# 3065PNPIMH register map
File version: 1.0
Registers are 32-bit, access per field, reset 0x0 unless marked. A register's access mark holds for its fields unless they carry their own. Offsets are from the block's base; [hi:lo] are bit positions; {n}, {i} and the like mark numbered series.

## CRG — CRG peripheral interface
Base 0x10000000
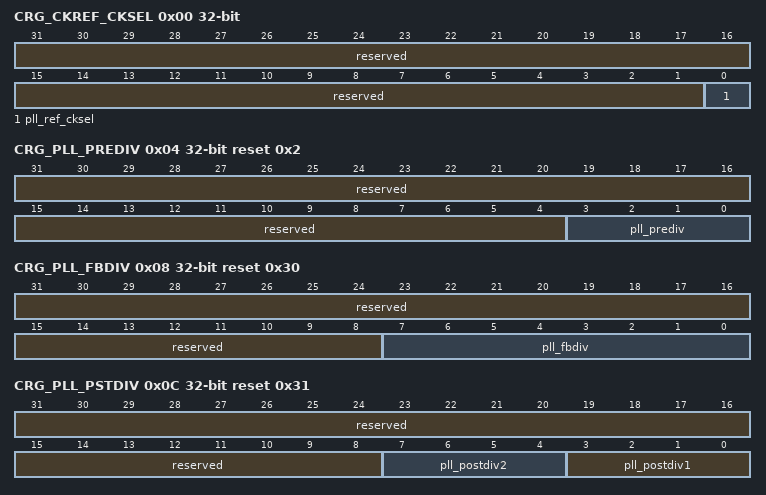
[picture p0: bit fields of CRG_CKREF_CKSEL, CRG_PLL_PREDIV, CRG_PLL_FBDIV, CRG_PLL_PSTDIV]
0x00 CRG_CKREF_CKSEL — CRG_CKREF_CKSEL为PLL配置寄存器0。 该寄存器可以被寄存器SC_LOCKEN[crg_cfg_lock]写保护控制，只有禁用写保护时，对这个寄存器的写操作才有效。
  [31:1] reserved ro — 保留。
  [0] pll_ref_cksel rw — PLL输入参考时钟clk_pll_ref时钟源选择信号。 0：选择clk_hosc； 1：选择clk_xtal。
0x04 CRG_PLL_PREDIV reset 0x2 — CRG_PLL_PREDIV为PLL配置寄存器1。 该寄存器可以被寄存器SC_LOCKEN[crg_cfg_lock]写保护控制，只有禁用写保护时，对这个寄存器的写操作才有效。
  [31:4] reserved ro — 保留。
  [3:0] pll_prediv rw — PLL内部前置分频器分频比。 0x0：1分频； 0x1：2分频； 0x2：3分频； 0x3：4分频； 0x4：5分频； 0x5：6分频； 0x6：7分频； 0x7：8分频； 其他：未使用。
0x08 CRG_PLL_FBDIV reset 0x30 — CRG_PLL_FBDIV为PLL配置寄存器2。 该寄存器可以被寄存器SC_LOCKEN[crg_cfg_lock]写保护控制，只有禁用写保护时，对这个寄存器的写操作才有效。
  [31:8] reserved ro — 保留。
  [7:0] pll_fbdiv rw — PLL内部反馈分频器分频比。 0x00 ～ 0x06：6分频； 0x07 ~ 0x7F：7~127分频； 其他：未使用。
0x0C CRG_PLL_PSTDIV reset 0x31 — CRG_PLL_PSTDIV为PLL配置寄存器3。 该寄存器可以被寄存器SC_LOCKEN[crg_cfg_lock]写保护控制，只有禁用写保护时，对这个寄存器的写操作才有效。
  [31:8] reserved ro — 保留。
  [7:4] pll_postdiv2 rw — PLL内部后置分频器分频比。 0x0：1分频； 0x1：2分频； 0x2：3分频； 0x3：4分频； 0x4：5分频； 0x5：6分频； 0x6：7分频； 0x7：8分频； 其他：未使用。
  [3:0] pll_postdiv1 rw — PLL内部后置分频器分频比。 0x0：1分频； 0x1：2分频； 0x2：3分频； 0x3：4分频； 0x4：5分频； 0x5：6分频； 0x6：7分频； 0x7：8分频； 其他：未使用。
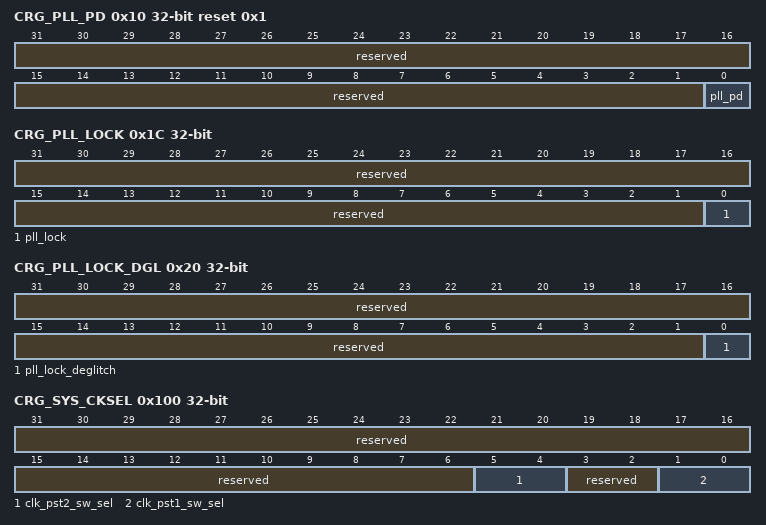
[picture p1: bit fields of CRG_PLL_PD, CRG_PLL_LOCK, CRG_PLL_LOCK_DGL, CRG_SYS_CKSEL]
0x10 CRG_PLL_PD reset 0x1 — CRG_PLL_PD为PLL配置寄存器4。 该寄存器可以被寄存器SC_LOCKEN[crg_cfg_lock]写保护控制，只有禁用写保护时，对这个寄存器的写操作才有效。
  [31:1] reserved ro — 保留。
  [0] pll_pd rw — PLL使能控制。 0：PLL上电使能； 1：PLL下电关闭。
0x1C CRG_PLL_LOCK ro — CRG_PLL_LOCK为PLL输出时钟频率稳定标志寄存器。
  [31:1] reserved — 保留。
  [0] pll_lock — PLL时钟稳定标志位信号。 0：PLL输出频率未稳定； 1：PLL输出频率稳定。
0x20 CRG_PLL_LOCK_DGL ro — CRG_PLL_LOCK_DGL为PLL输出lock去毛刺信号寄存器。
  [31:1] reserved — 保留。
  [0] pll_lock_deglitch — pll lock硬件虑毛刺之后信号。
0x100 CRG_SYS_CKSEL — CRG_SYS_CKSEL为系统时钟控制寄存器。 该寄存器可以被寄存器SC_LOCKEN[crg_cfg_lock]写保护控制，只有禁用写保护时，对这个寄存器的写操作才有效。
  [31:6] reserved ro — 保留。
  [5:4] clk_pst2_sw_sel rw — clk_pst2_100m时钟选择信号。 00：选择clk_hosc； 01：选择clk_xtal； 10：选择clk_pll_pst2； 11：保留。
  [3:2] reserved ro — 保留。
  [1:0] clk_pst1_sw_sel rw — clk_sys时钟选择信号。 00：选择clk_hosc； 01：选择clk_xtal； 10：选择clk_pll_pst1； 11：保留。
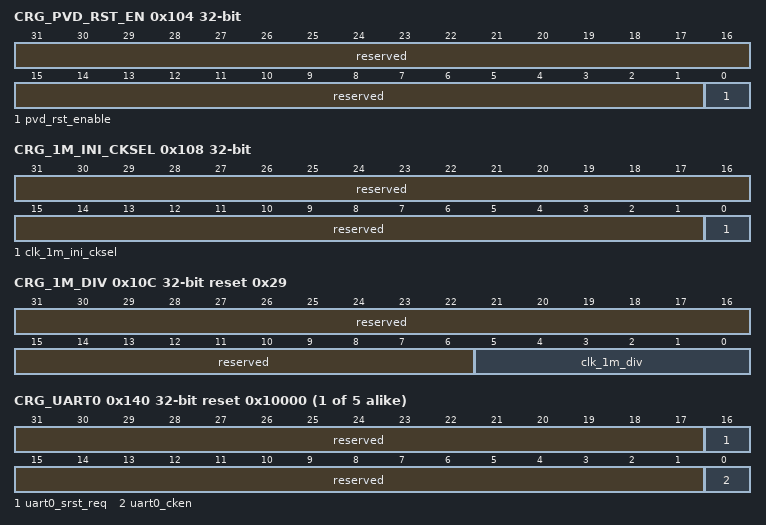
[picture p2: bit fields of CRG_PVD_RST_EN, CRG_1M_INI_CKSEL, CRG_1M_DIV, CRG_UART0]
0x104 CRG_PVD_RST_EN — CRG_PVD_RST_EN为PVD复位控制寄存器。
  [31:1] reserved ro — 保留。
  [0] pvd_rst_enable rw — PVD复位使能。 0：不使能； 1：使能。
0x108 CRG_1M_INI_CKSEL — CRG_1M_INI_CKSEL为CLK_1M时钟源头选择控制寄存器。
  [31:1] reserved ro — 保留。
  [0] clk_1m_ini_cksel rw — 1MHz时钟和clk_bg_chopper时钟的源头时钟选择信号。 0：选择clk_hosc，默认； 1：选择clk_xtal。
0x10C CRG_1M_DIV reset 0x29 — CRG_1M_DIV为CLK_1M时钟分频控制寄存器。
  [31:6] reserved ro — 保留。
  [5:0] clk_1m_div rw — clk_1m时钟分频参数，配置范围为[0～63]。 输出时钟频率为输入时钟频率/(clk_1m_div + 1)。 默认42分频，配'd29。
{0x140+4i} CRG_UART{i} reset 0x10000 (i=0..4) — CRG_UART{i}为UART{i}时钟及软复位控制寄存器。
  [31:17] reserved ro — 保留。
  [16] uart{i}_srst_req rw — UART{i}软复位请求。 0：不复位； 1：复位。
  [15:1] reserved ro — 保留。
  [0] uart{i}_cken rw — UART{i}时钟门控。 0：关断； 1：打开。
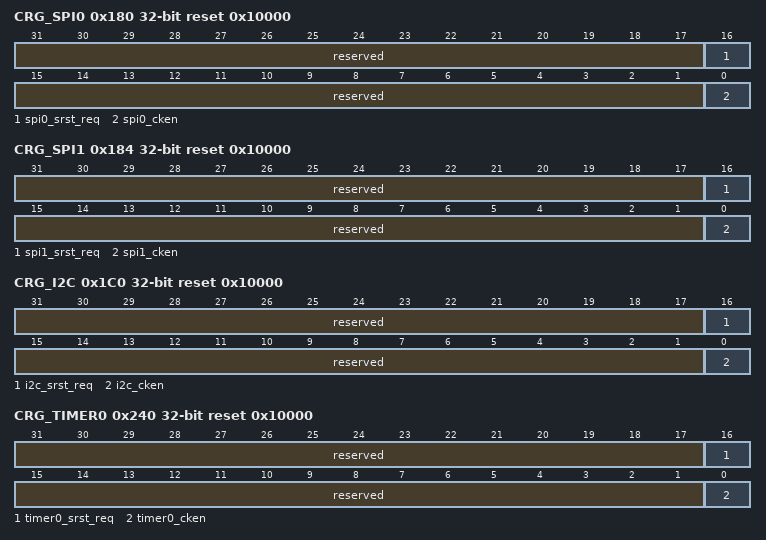
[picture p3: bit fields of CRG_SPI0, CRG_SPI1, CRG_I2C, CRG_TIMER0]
0x180 CRG_SPI0 reset 0x10000 — CRG_SPI0为SPI0时钟及软复位控制寄存器。
  [31:17] reserved ro — 保留。
  [16] spi0_srst_req rw — SPI0软复位请求。 0：不复位； 1：复位。
  [15:1] reserved ro — 保留。
  [0] spi0_cken rw — SPI0时钟门控。 0：关断； 1：打开。
0x184 CRG_SPI1 reset 0x10000 — CRG_SPI1为SPI1时钟及软复位控制寄存器。
  [31:17] reserved ro — 保留。
  [16] spi1_srst_req rw — SPI1软复位请求。 0：不复位； 1：复位。
  [15:1] reserved ro — 保留。
  [0] spi1_cken rw — SPI1时钟门控。 0：关断； 1：打开。
0x1C0 CRG_I2C reset 0x10000 — CRG_I2C为I2C时钟及软复位控制寄存器。
  [31:17] reserved ro — 保留。
  [16] i2c_srst_req rw — I2C软复位请求。 0：不复位； 1：复位。
  [15:1] reserved ro — 保留。
  [0] i2c_cken rw — I2C时钟门控。 0：关断； 1：打开。
0x240 CRG_TIMER0 reset 0x10000 — CRG_TIMER0为Timer0时钟及软复位控制寄存器。
  [31:17] reserved ro — 保留。
  [16] timer0_srst_req rw — Timer0软复位请求。 0：不复位； 1：复位。
  [15:1] reserved ro — 保留。
  [0] timer0_cken rw — Timer0时钟门控。 0：关断； 1：打开。
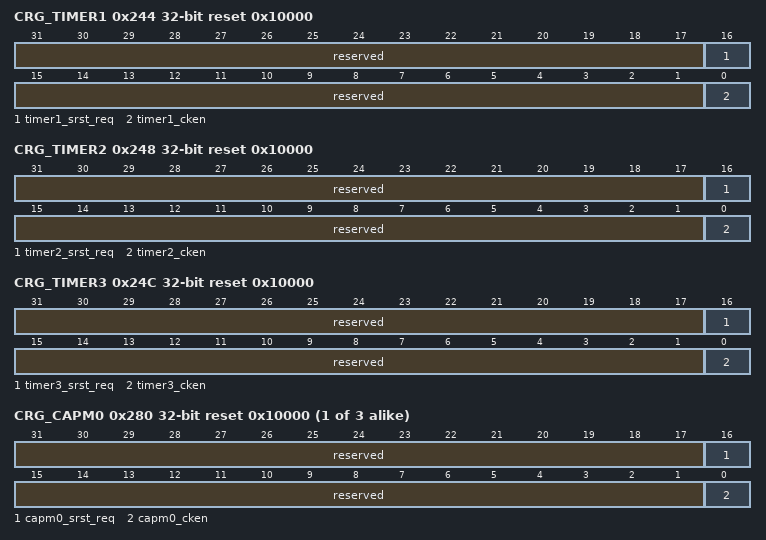
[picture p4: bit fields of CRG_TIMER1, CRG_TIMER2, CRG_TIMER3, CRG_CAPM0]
0x244 CRG_TIMER1 reset 0x10000 — CRG_TIMER1为Timer1时钟及软复位控制寄存器。
  [31:17] reserved ro — 保留。
  [16] timer1_srst_req rw — Timer1软复位请求。 0：不复位； 1：复位。
  [15:1] reserved ro — 保留。
  [0] timer1_cken rw — Timer1时钟门控。 0：关断； 1：打开。
0x248 CRG_TIMER2 reset 0x10000 — CRG_TIMER2为Timer2时钟及软复位控制寄存器。
  [31:17] reserved ro — 保留。
  [16] timer2_srst_req rw — Timer2软复位请求。 0：不复位； 1：复位。
  [15:1] reserved ro — 保留
  [0] timer2_cken rw — Timer2时钟门控。 0：关断； 1：打开。
0x24C CRG_TIMER3 reset 0x10000 — CRG_TIMER3为Timer3时钟及软复位控制寄存器。
  [31:17] reserved ro — 保留。
  [16] timer3_srst_req rw — Timer3软复位请求。 0：不复位； 1：复位。
  [15:1] reserved ro — 保留。
  [0] timer3_cken rw — Timer3时钟门控。 0：关断； 1：打开。
{0x280+4i} CRG_CAPM{i} reset 0x10000 (i=0..2) — CRG_CAPM{i}为CAPM{i}时钟及软复位控制寄存器。
  [31:17] reserved ro — 保留。
  [16] capm{i}_srst_req rw — CAPM{i}软复位请求。 0：不复位； 1：复位。
  [15:1] reserved ro — 保留。
  [0] capm{i}_cken rw — CAPM{i}时钟门控。 0：关断； 1：打开。
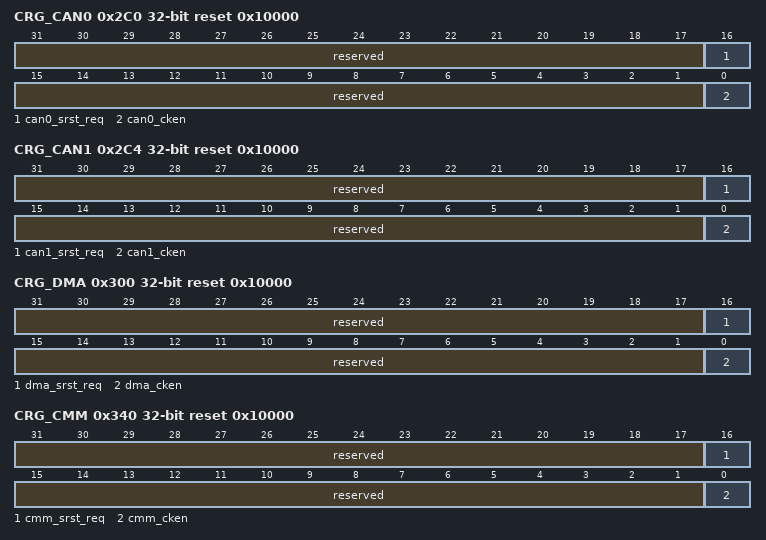
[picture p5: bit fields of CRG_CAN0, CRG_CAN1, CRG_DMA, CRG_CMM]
0x2C0 CRG_CAN0 reset 0x10000 — CRG_CAN0为CAN0时钟及软复位控制寄存器。
  [31:17] reserved ro — 保留。
  [16] can0_srst_req rw — CAN0软复位请求。 0：不复位； 1：复位。
  [15:1] reserved ro — 保留。
  [0] can0_cken rw — CAN0时钟门控。 0：关断； 1：打开。
0x2C4 CRG_CAN1 reset 0x10000 — CRG_CAN1为CAN1时钟及软复位控制寄存器。
  [31:17] reserved ro — 保留。
  [16] can1_srst_req rw — CAN1软复位请求。 0：不复位； 1：复位。
  [15:1] reserved ro — 保留。
  [0] can1_cken rw — CAN1时钟门控。 0：关断； 1：打开。
0x300 CRG_DMA reset 0x10000 — CRG_DMA为DMA时钟及软复位控制寄存器。
  [31:17] reserved ro — 保留。
  [16] dma_srst_req rw — DMA软复位请求。 0：不复位； 1：复位。
  [15:1] reserved ro — 保留。
  [0] dma_cken rw — DMA时钟门控。 0：关断； 1：打开。
0x340 CRG_CMM reset 0x10000 — CRG_CMM为CMM时钟及软复位控制寄存器。
  [31:17] reserved ro — 保留。
  [16] cmm_srst_req rw — CMM软复位请求。 0：不复位； 1：复位。
  [15:1] reserved ro — 保留。
  [0] cmm_cken rw — CMM时钟门控。 0：关断； 1：打开。
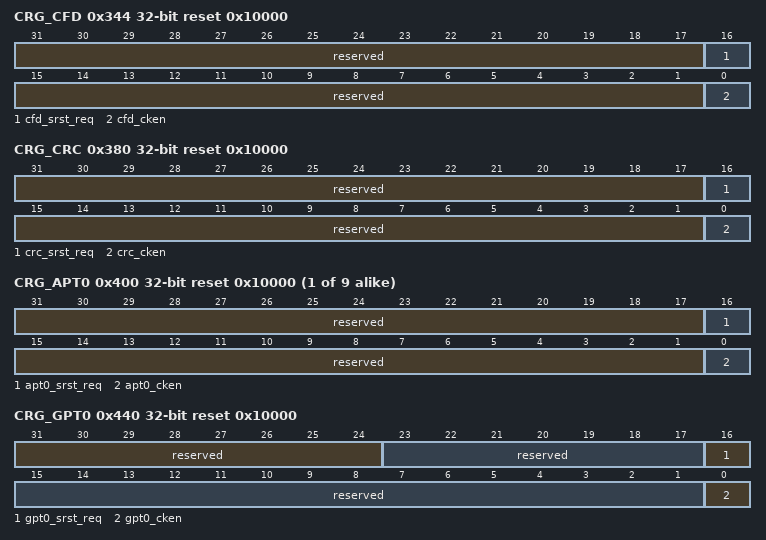
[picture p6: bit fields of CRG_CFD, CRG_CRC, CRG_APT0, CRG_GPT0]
0x344 CRG_CFD reset 0x10000 — CRG_CFD为CFD时钟及软复位控制寄存器。
  [31:17] reserved ro — 保留。
  [16] cfd_srst_req rw — CFD软复位请求。 0：不复位； 1：复位。
  [15:1] reserved ro — 保留。
  [0] cfd_cken rw — CFD时钟门控。 0：关断； 1：打开。
0x380 CRG_CRC reset 0x10000 — CRG_CRC为CRC时钟及软复位控制寄存器。
  [31:17] reserved ro — 保留。
  [16] crc_srst_req rw — CRC软复位请求。 0：不复位； 1：复位。
  [15:1] reserved ro — 保留。
  [0] crc_cken rw — CRC时钟门控。 0：关断； 1：打开。
{0x400+4i} CRG_APT{i} reset 0x10000 (i=0..8) — CRG_APT{i}为APT{i}时钟及软复位控制寄存器。
  [31:17] reserved ro — 保留。
  [16] apt{i}_srst_req rw — APT{i}软复位请求。 0：不复位； 1：复位。
  [15:1] reserved ro — 保留。
  [0] apt{i}_cken rw — APT{i}时钟门控。 0：关断； 1：打开。
0x440 CRG_GPT0 reset 0x10000 — CRG_GPT0为GPT0时钟及软复位控制寄存器。
  [31:24] reserved ro — 保留。
  [23:17] reserved ro — 保留。
  [16] gpt0_srst_req rw — GPT0软复位请求。 0：不复位； 1：复位。
  [15:1] reserved ro — 保留。
  [0] gpt0_cken rw — GPT0时钟门控。 0：关断； 1：打开。
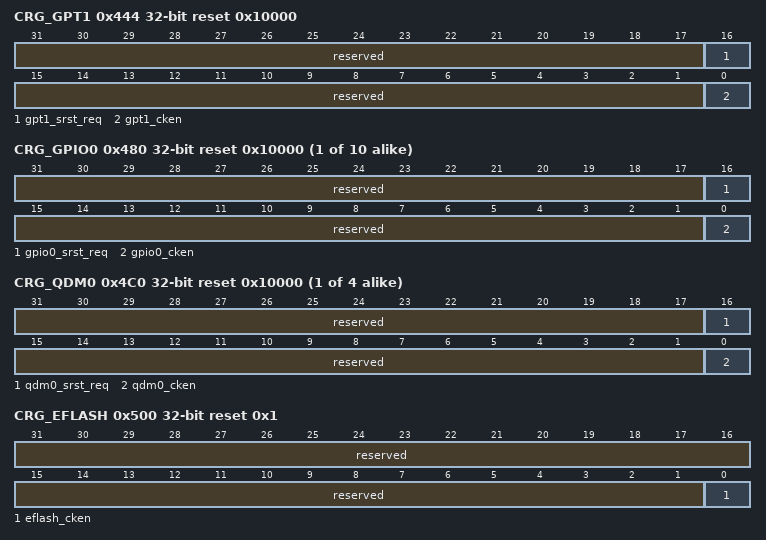
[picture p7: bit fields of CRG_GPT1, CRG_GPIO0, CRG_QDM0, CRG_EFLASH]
0x444 CRG_GPT1 reset 0x10000 — CRG_GPT1为GPT1时钟及软复位控制寄存器。
  [31:17] reserved ro — 保留。
  [16] gpt1_srst_req rw — GPT1软复位请求。 0：不复位； 1：复位。
  [15:1] reserved ro — 保留。
  [0] gpt1_cken rw — GPT1时钟门控。 0：关断； 1：打开。
{0x480+4i} CRG_GPIO{i} reset 0x10000 (i=0..9) — CRG_GPIO{i}为GPIO{i}时钟及软复位控制寄存器。
  [31:17] reserved ro — 保留。
  [16] gpio{i}_srst_req rw — GPIO{i}软复位请求。 0：不复位； 1：复位。
  [15:1] reserved ro — 保留。
  [0] gpio{i}_cken rw — GPIO{i}时钟门控。 0：关断； 1：打开。
{0x4C0+4i} CRG_QDM{i} reset 0x10000 (i=0..3) — CRG_QDM{i}为QDM{i}时钟及软复位控制寄存器。
  [31:17] reserved ro — 保留。
  [16] qdm{i}_srst_req rw — QDM{i}软复位请求。 0：不复位； 1：复位。
  [15:1] reserved ro — 保留。
  [0] qdm{i}_cken rw — QDM{i}时钟门控。 0：关断； 1：打开。
0x500 CRG_EFLASH access not given reset 0x1 — CRG_EFLASH为Flash时钟控制寄存器。 该寄存器可以被寄存器SC_LOCKEN[crg_cfg_lock]写保护控制，只有禁用写保护时，对这个寄存器的写操作才有效。
  [31:1] reserved ro — 保留。
  [0] eflash_cken — Flash时钟门控。 0：关断； 1：打开。
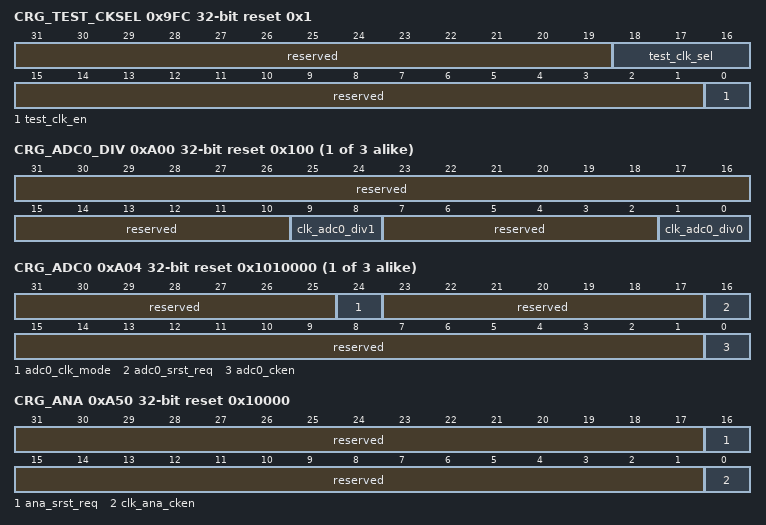
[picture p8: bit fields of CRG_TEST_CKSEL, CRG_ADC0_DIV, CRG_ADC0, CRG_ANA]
0x9FC CRG_TEST_CKSEL reset 0x1 — CRG_TEST_CKSEL为TEST时钟选择控制寄存器。
  [31:19] reserved ro — 保留。
  [18:16] test_clk_sel rw — TEST_CLK时钟选择。 000：pll_pfd； 001：clk_hosc； 010：clk_losc； 011：clk_xtal； 100：clk_bg_chopper； 101：clk_adc0/4； 110：clk_sys/6; 111：clk_hosc_div。
  [15:1] reserved ro — 保留。
  [0] test_clk_en rw — test_clk_en。 0：不使能； 1：使能。
{0xA00+8i} CRG_ADC{i}_DIV reset 0x100 (i=0..2) — CRG_ADC{i}_DIV为ADC{i}分频时钟配置寄存器。
  [31:10] reserved ro — 保留。
  [9:8] clk_adc{i}_div1 rw — clk_adc{i}选择clk_sys通路的时钟分频参数，配置范围[0～3]。 输出时钟频率为clk_sys/(clk_adc{i}_div1 + 1)。 默认二分频，配1。
  [7:2] reserved ro — 保留。
  [1:0] clk_adc{i}_div0 rw — clk_adc{i}选择clk_pst2_100m通路的时钟分频参数，配置范围[0～3]。 输出时钟频率为clk_pst2_100m/(clk_adc{i}_div0 + 1)。 默认不分频，配0。
{0xA04+8i} CRG_ADC{i} reset 0x1010000 (i=0..2) — CRG_ADC{i}为ADC{i}时钟及软复位控制寄存器。
  [31:25] reserved ro — 保留。
  [24] adc{i}_clk_mode rw — ADC{i}时钟源选择信号。 0：clk_pst2_100m经过分频后的时钟； 1：clk_sys经过分频后的时钟。
  [23:17] reserved ro — 保留。
  [16] adc{i}_srst_req rw — ADC{i}软复位请求。 0：不复位； 1：复位。
  [15:1] reserved ro — 保留。
  [0] adc{i}_cken rw — ADC{i}时钟门控。 0：关断； 1：打开。
0xA50 CRG_ANA reset 0x10000 — CRG_ANA为ANA时钟控制寄存器。
  [31:17] reserved ro — 保留。
  [16] ana_srst_req rw — ANA软复位请求。 0：不复位； 1：复位。
  [15:1] reserved ro — 保留。
  [0] clk_ana_cken rw — ANA时钟门控。 0：关断； 1：打开。
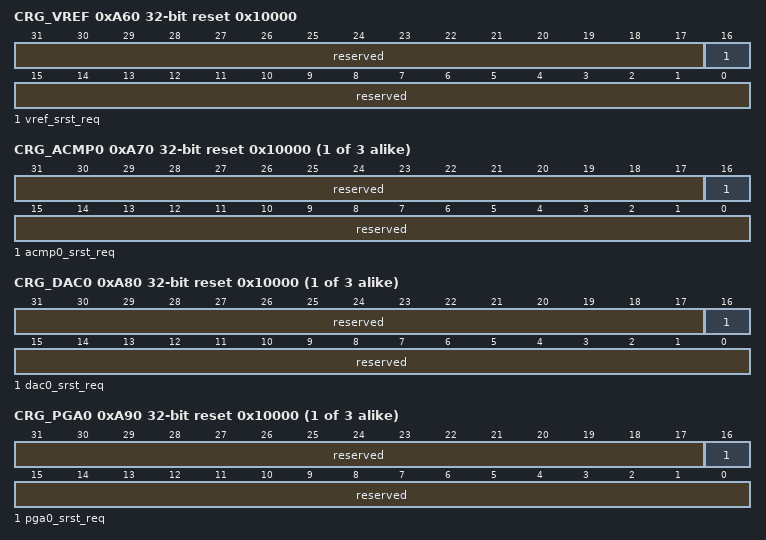
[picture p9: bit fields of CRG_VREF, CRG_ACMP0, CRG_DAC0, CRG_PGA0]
0xA60 CRG_VREF reset 0x10000 — CRG_VREF为VREF软复位请求寄存器。
  [31:17] reserved ro — 保留。
  [16] vref_srst_req rw — VREF软复位请求。 0：不复位； 1：复位。
  [15:0] reserved ro — 保留。
{0xA70+4i} CRG_ACMP{i} reset 0x10000 (i=0..2) — CRG_ACMP{i}为ACMP{i}软复位请求寄存器。
  [31:17] reserved ro — 保留。
  [16] acmp{i}_srst_req rw — ACMP{i}软复位请求。 0：不复位； 1：复位。
  [15:0] reserved ro — 保留。
{0xA80+4i} CRG_DAC{i} reset 0x10000 (i=0..2) — CRG_DAC{i}为DAC{i}软复位请求寄存器。
  [31:17] reserved ro — 保留。
  [16] dac{i}_srst_req rw — DAC{i}软复位请求。 0：不复位； 1：复位。
  [15:0] reserved ro — 保留。
{0xA90+4i} CRG_PGA{i} reset 0x10000 (i=0..2) — CRG_PGA{i}为PGA{i}软复位请求寄存器。
  [31:17] reserved ro — 保留。
  [16] pga{i}_srst_req rw — PGA{i}软复位请求。 0：不复位； 1：复位。
  [15:0] reserved ro — 保留。
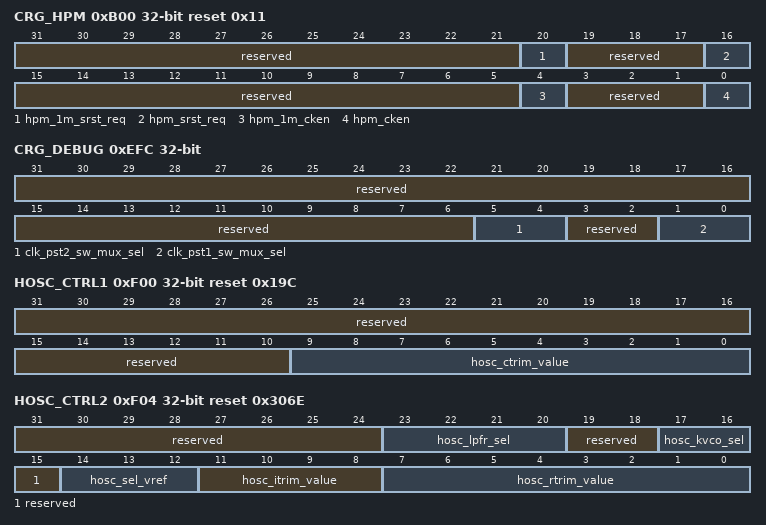
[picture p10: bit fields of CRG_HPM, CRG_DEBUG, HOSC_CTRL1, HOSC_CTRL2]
0xB00 CRG_HPM reset 0x11 — CRG_HPM为HPM时钟及软复位控制寄存器。
  [31:21] reserved ro — 保留。
  [20] hpm_1m_srst_req rw — HPM 1MHz时钟域软复位请求。 0：不复位； 1：复位。
  [19:17] reserved ro — 保留。
  [16] hpm_srst_req rw — HPM 系统时钟域软复位请求。 0：不复位； 1：复位。
  [15:5] reserved ro — 保留。
  [4] hpm_1m_cken rw — HPM 1MHz时钟门控。 0：关断； 1：打开。
  [3:1] reserved ro — 保留。
  [0] hpm_cken rw — HPM 系统时钟门控。 0：关断； 1：打开。
0xEFC CRG_DEBUG ro — CRG_DEBUG为DEBUG寄存器。
  [31:6] reserved — 保留。
  [5:4] clk_pst2_sw_mux_sel — clk_pst2_sw_mux_sel信号。
  [3:2] reserved — 保留。
  [1:0] clk_pst1_sw_mux_sel — hclk_sw_mux_sel信号。
0xF00 HOSC_CTRL1 reset 0x19C — HOSC_CTRL1为HOSC配置寄存器。
  [31:10] reserved ro — 保留。
  [9:0] hosc_ctrim_value rw — OSC25M frequency trimming controlled be Efuse bit[9:1]: 512 steps calib Cdac= 1.542p+ 7.46f*ctrim[9:1] bit[0]: 2 steps calib Cdac= 3.725f*ctrim[0]
0xF04 HOSC_CTRL2 reset 0x306E — HOSC_CTRL2为HOSC配置寄存器。
  [31:24] reserved ro — 保留。
  [23:20] hosc_lpfr_sel rw — bit[3:2]：Reserved。 bit[1]：VREF RC short control signal。 0：RC short； 1：RC not short。 bit[0]：FS ENB signal。 0：FS enable； 1：FS disable。
  [19:18] reserved ro — 保留。
  [17:16] hosc_kvco_sel rw — Select KVCO ratio。 00：9:1； 01：6:1； 10：6:1； 11：4.5:1。
  [15] reserved ro — 保留。
  [14:12] hosc_sel_vref rw — Select vref of OSC to change fosc25M。 000：19.60M； 001：21M； 010：22.76M； 011：25M (default) 0.9V； 100：28.06M； 101：32.15M； 110：38.26M； 111：48.34M。
  [11:8] hosc_itrim_value rw — 保留。
  [7:0] hosc_rtrim_value rw — bit[7]：reserved; bit[6:0]：Select for vref thermal coefficient: 7’b1101110 +0.63%； 7’b0011110 +0.54%； 7’b1111001 +0.49%； 7’b1110101 -0.38%； 7’b1101101 -0.47%； 7’b0111101 -0.55%； 7’b1110011 -0.61%。
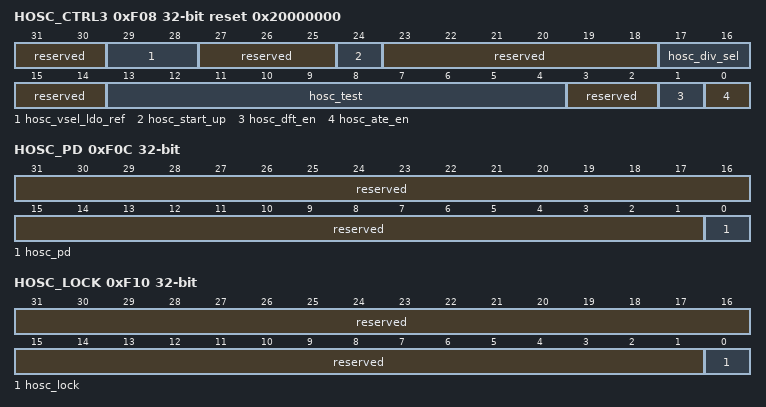
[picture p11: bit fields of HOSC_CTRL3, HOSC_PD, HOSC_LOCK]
0xF08 HOSC_CTRL3 reset 0x20000000 — HOSC_CTRL3为HOSC配置寄存器。
  [31:30] reserved ro — 保留。
  [29:28] hosc_vsel_ldo_ref rw — Select 1.8V LDO output voltage。 00：1.8V； 01：1.86V； 10：1.9V； 11：1.98V。
  [27:25] reserved ro — 保留。
  [24] hosc_start_up rw — Output reset signal。 0：disabled； 1：reset vctrl in OSC analog phy。 Reserved
  [23:18] reserved ro — 保留。
  [17:16] hosc_div_sel rw — Select mode of internal divider for CLK_DIV_OUT。 00：1024； 01：2048； 10：512； 11：256。
  [15:14] reserved ro — 保留。
  [13:4] hosc_test rw — bit[9]：select IBIAS bypass signal。 0：use normal mode； 1：use bypass mode。 bit[8]：select LDO bypass signal。 0：use normal mode； 1：use bypass mode。 bit[7]：reserved。 bit[6]：select ad_test_dig signal。 0：use CLK_DIV_OUT； 1：use CLK_OUT。 bit[5:3]：select test_analog signal。 000：reserved； 001：test avdd18； 010：test vctrl； 011：test vring； 100：test vref； 101：test lock； 110：test reset18； 111：test fs_ctl18。 bit[2]：Voltage divider control signal。 0：test voltage halved； 1：test voltage not divided 。 bit[1]：select test voltage output mode。 0：direct output ； 1：OP buffer。 bit[0]：analog test control signal。 0：analog test disable； 1：analog test enable。
  [3:2] reserved ro — 保留。
  [1] hosc_dft_en rw — Flag of DFT mode。 0：when REG_ATE_EN=0,CLK_OUT_ANALOG=CLK_OSC When REG_ATE_EN=1, CLK_OUT_ANALOG=CLK_XTAL； 1：CLK_OUT_ANALOG=CLK_OSC。
  [0] hosc_ate_en rw — Switch to ATE mode。 0：not in ATE mode； 1：in ATE mode。
0xF0C HOSC_PD — HOSC_PD为HOSC配置寄存器。 该寄存器可以被寄存器SC_LOCKEN[crg_cfg_lock]写保护控制，只有禁用写保护时，对这个寄存器的写操作才有效。
  [31:1] reserved ro — 保留
  [0] hosc_pd rw — HOSC使能信号。 0：HOSC上电使能； 1：HOSC下电关闭。
0xF10 HOSC_LOCK ro — HOSC_LOCK为HOSC输出时钟频率稳定标志寄存器。
  [31:1] reserved — 保留。
  [0] hosc_lock — HOSC时钟稳定标志位信号。 0：HOSC输出频率未稳定； 1：HOSC输出频率稳定。
